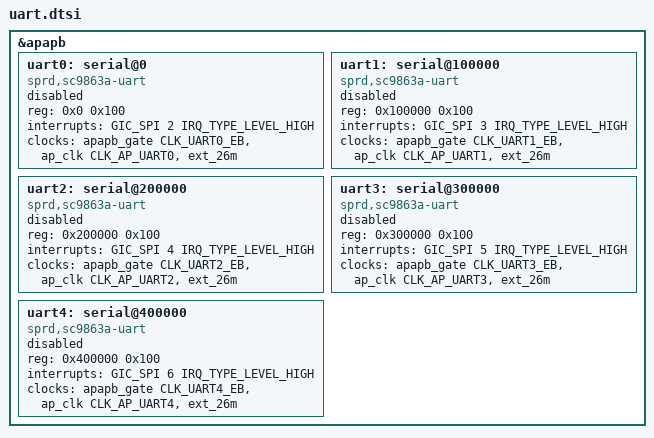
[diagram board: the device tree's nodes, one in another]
// SPDX-License-Identifier: (GPL-2.0+ OR MIT)
/*
 * Unisoc UART dts file
 *
 * Copyright (C) 2023, Unisoc Inc.
 *
 */

&apapb {
	uart0: serial@0 {
		compatible = "sprd,sc9863a-uart",
			     "sprd,sc9836-uart";
		reg = <0x0 0x100>;
		interrupts = <GIC_SPI 2 IRQ_TYPE_LEVEL_HIGH>;
		clock-names = "enable", "uart", "source";
		clocks = <&apapb_gate CLK_UART0_EB>,
			<&ap_clk CLK_AP_UART0>, <&ext_26m>;
		status = "disabled";
	};

	uart1: serial@100000 {
		compatible = "sprd,sc9863a-uart",
			     "sprd,sc9836-uart";
		reg = <0x100000 0x100>;
		interrupts = <GIC_SPI 3 IRQ_TYPE_LEVEL_HIGH>;
		clock-names = "enable", "uart", "source";
		clocks = <&apapb_gate CLK_UART1_EB>,
			<&ap_clk CLK_AP_UART1>, <&ext_26m>;
		status = "disabled";
	};

	uart2: serial@200000 {
		compatible = "sprd,sc9863a-uart",
			     "sprd,sc9836-uart";
		reg = <0x200000 0x100>;
		interrupts = <GIC_SPI 4 IRQ_TYPE_LEVEL_HIGH>;
		clock-names = "enable", "uart", "source";
		clocks = <&apapb_gate CLK_UART2_EB>,
			<&ap_clk CLK_AP_UART2>, <&ext_26m>;
		status = "disabled";
	};

	uart3: serial@300000 {
		compatible = "sprd,sc9863a-uart",
			     "sprd,sc9836-uart";
		reg = <0x300000 0x100>;
		interrupts = <GIC_SPI 5 IRQ_TYPE_LEVEL_HIGH>;
		clock-names = "enable", "uart", "source";
		clocks = <&apapb_gate CLK_UART3_EB>,
			<&ap_clk CLK_AP_UART3>, <&ext_26m>;
		status = "disabled";
	};
	uart4: serial@400000 {
		compatible = "sprd,sc9863a-uart",
			     "sprd,sc9836-uart";
		reg = <0x400000 0x100>;
		interrupts = <GIC_SPI 6 IRQ_TYPE_LEVEL_HIGH>;
		clock-names = "enable", "uart", "source";
		clocks = <&apapb_gate CLK_UART4_EB>,
			<&ap_clk CLK_AP_UART4>, <&ext_26m>;
		status = "disabled";
	};
};
